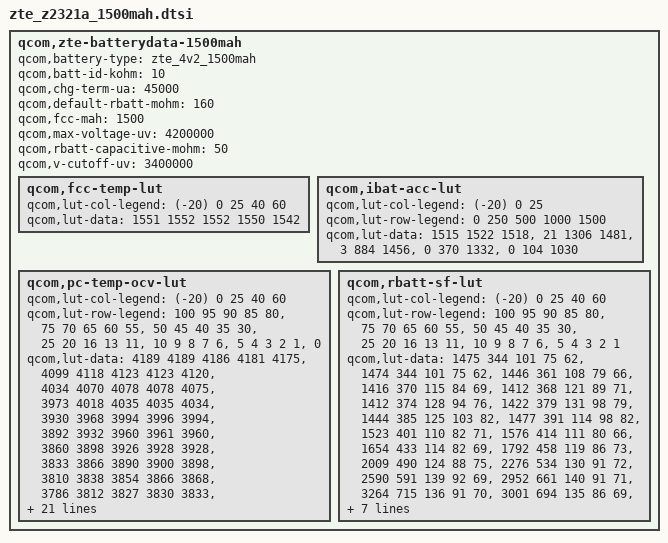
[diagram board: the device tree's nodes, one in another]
/* Copyright (c) 2014, The Linux Foundation. All rights reserved.
 *
 * This program is free software; you can redistribute it and/or modify
 * it under the terms of the GNU General Public License version 2 and
 * only version 2 as published by the Free Software Foundation.
 *
 * This program is distributed in the hope that it will be useful,
 * but WITHOUT ANY WARRANTY; without even the implied warranty of
 * MERCHANTABILITY or FITNESS FOR A PARTICULAR PURPOSE.  See the
 * GNU General Public License for more details.
 */

qcom,zte-batterydata-1500mah {
	qcom,battery-type = "zte_4v2_1500mah";
	qcom,batt-id-kohm = <10>;
	qcom,chg-term-ua = <45000>;
	qcom,default-rbatt-mohm = <160>;
	qcom,fcc-mah = <1500>;
	qcom,max-voltage-uv = <4200000>;
	qcom,rbatt-capacitive-mohm = <50>;
	qcom,v-cutoff-uv = <3400000>;

	qcom,fcc-temp-lut {
		qcom,lut-col-legend = <(-20) 0 25 40 60>;
		qcom,lut-data = <1551 1552 1552 1550 1542>;
	};

	qcom,ibat-acc-lut {
		qcom,lut-col-legend = <(-20) 0 25>;
		qcom,lut-row-legend = <0 250 500 1000 1500>;
		qcom,lut-data = <1515 1522 1518>,
				<21 1306 1481>,
				<3 884 1456>,
				<0 370 1332>,
				<0 104 1030>;
	};

	qcom,pc-temp-ocv-lut {
		qcom,lut-col-legend = <(-20) 0 25 40 60>;
		qcom,lut-row-legend = <100 95 90 85 80>,
					<75 70 65 60 55>,
					<50 45 40 35 30>,
					<25 20 16 13 11>,
					<10 9 8 7 6>,
					<5 4 3 2 1>,
					<0>;
		qcom,lut-data = <4189 4189 4186 4181 4175>,
				<4099 4118 4123 4123 4120>,
				<4034 4070 4078 4078 4075>,
				<3973 4018 4035 4035 4034>,
				<3930 3968 3994 3996 3994>,
				<3892 3932 3960 3961 3960>,
				<3860 3898 3926 3928 3928>,
				<3833 3866 3890 3900 3898>,
				<3810 3838 3854 3866 3868>,
				<3786 3812 3827 3830 3833>,
				<3766 3792 3806 3808 3808>,
				<3745 3776 3788 3790 3790>,
				<3726 3762 3775 3776 3776>,
				<3707 3750 3765 3764 3764>,
				<3688 3740 3756 3755 3748>,
				<3666 3729 3746 3742 3730>,
				<3644 3716 3724 3720 3708>,
				<3626 3701 3694 3688 3676>,
				<3614 3686 3680 3674 3663>,
				<3600 3674 3676 3671 3661>,
				<3591 3668 3673 3670 3660>,
				<3580 3660 3671 3667 3658>,
				<3567 3652 3667 3664 3654>,
				<3552 3642 3658 3656 3643>,
				<3535 3624 3638 3632 3616>,
				<3512 3598 3598 3590 3574>,
				<3482 3555 3543 3534 3522>,
				<3440 3495 3472 3466 3457>,
				<3374 3406 3380 3378 3374>,
				<3258 3270 3253 3252 3248>,
				<3000 3000 3000 3000 3000>;
	};

	qcom,rbatt-sf-lut {
		qcom,lut-col-legend = <(-20) 0 25 40 60>;
		qcom,lut-row-legend = <100 95 90 85 80>,
					<75 70 65 60 55>,
					<50 45 40 35 30>,
					<25 20 16 13 11>,
					<10 9 8 7 6>,
					<5 4 3 2 1>;
		qcom,lut-data = <1475 344 101 75 62>,
				<1474 344 101 75 62>,
				<1446 361 108 79 66>,
				<1416 370 115 84 69>,
				<1412 368 121 89 71>,
				<1412 374 128 94 76>,
				<1422 379 131 98 79>,
				<1444 385 125 103 82>,
				<1477 391 114 98 82>,
				<1523 401 110 82 71>,
				<1576 414 111 80 66>,
				<1654 433 114 82 69>,
				<1792 458 119 86 73>,
				<2009 490 124 88 75>,
				<2276 534 130 91 72>,
				<2590 591 139 92 69>,
				<2952 661 140 91 71>,
				<3264 715 136 91 70>,
				<3001 694 135 86 69>,
				<3331 729 145 94 72>,
				<3594 755 153 98 74>,
				<3883 785 161 101 77>,
				<4244 818 170 105 77>,
				<4695 856 178 108 76>,
				<5243 895 179 102 75>,
				<5939 942 178 102 75>,
				<6912 999 191 106 79>,
				<8293 1071 210 117 87>,
				<10424 1218 246 138 101>,
				<14456 1879 372 199 120>;
	};
};

